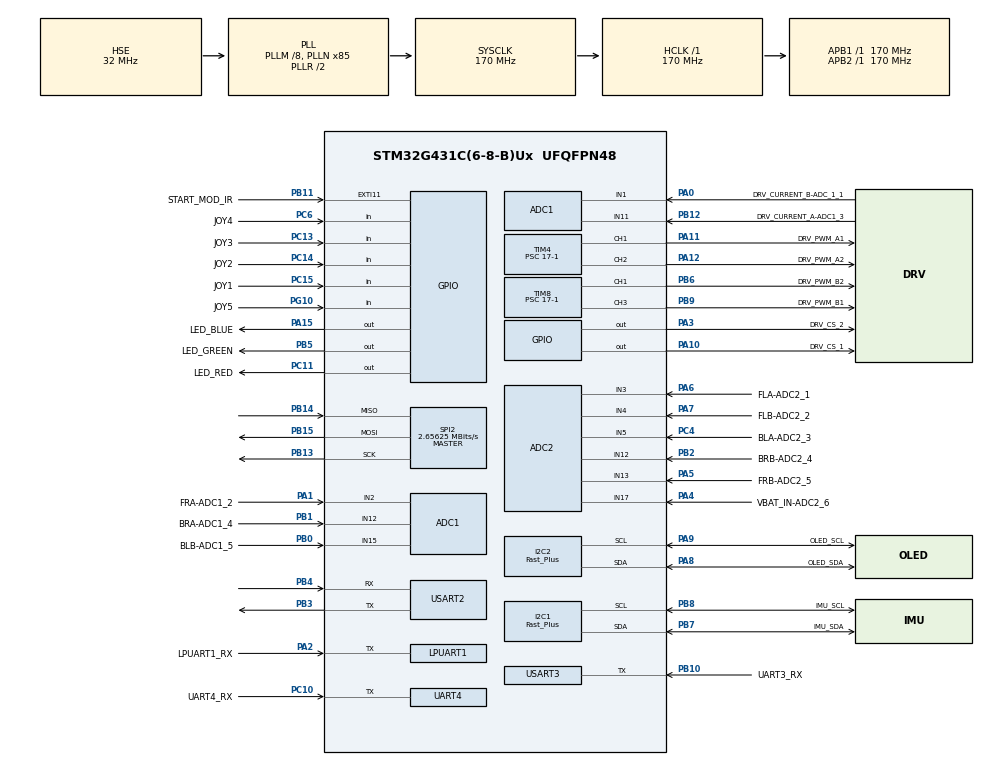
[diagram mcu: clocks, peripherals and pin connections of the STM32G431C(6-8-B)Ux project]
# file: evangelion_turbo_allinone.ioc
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ADC1.Channel-0\#ChannelRegularConversion=ADC_CHANNEL_1
ADC1.Channel-1\#ChannelRegularConversion=ADC_CHANNEL_2
ADC1.Channel-2\#ChannelRegularConversion=ADC_CHANNEL_11
ADC1.Channel-3\#ChannelRegularConversion=ADC_CHANNEL_12
ADC1.Channel-4\#ChannelRegularConversion=ADC_CHANNEL_15
ADC1.Channel-8\#ChannelRegularConversion=ADC_CHANNEL_TEMPSENSOR_ADC1
ADC1.ContinuousConvMode=ENABLE
ADC1.DMAContinuousRequests=ENABLE
ADC1.NbrOfConversion=6
ADC1.NbrOfConversionFlag=1
ADC1.OffsetNumber-0\#ChannelRegularConversion=ADC_OFFSET_NONE
ADC1.OffsetNumber-1\#ChannelRegularConversion=ADC_OFFSET_NONE
ADC1.OffsetNumber-2\#ChannelRegularConversion=ADC_OFFSET_NONE
ADC1.OffsetNumber-3\#ChannelRegularConversion=ADC_OFFSET_NONE
ADC1.OffsetNumber-4\#ChannelRegularConversion=ADC_OFFSET_NONE
ADC1.OffsetNumber-8\#ChannelRegularConversion=ADC_OFFSET_NONE
ADC1.Overrun=ADC_OVR_DATA_OVERWRITTEN
ADC1.Rank-0\#ChannelRegularConversion=1
ADC1.Rank-1\#ChannelRegularConversion=2
ADC1.Rank-2\#ChannelRegularConversion=3
ADC1.Rank-3\#ChannelRegularConversion=4
ADC1.Rank-4\#ChannelRegularConversion=5
ADC1.Rank-8\#ChannelRegularConversion=6
ADC1.SamplingTime-0\#ChannelRegularConversion=ADC_SAMPLETIME_640CYCLES_5
ADC1.SamplingTime-1\#ChannelRegularConversion=ADC_SAMPLETIME_92CYCLES_5
ADC1.SamplingTime-2\#ChannelRegularConversion=ADC_SAMPLETIME_92CYCLES_5
ADC1.SamplingTime-3\#ChannelRegularConversion=ADC_SAMPLETIME_92CYCLES_5
ADC1.SamplingTime-4\#ChannelRegularConversion=ADC_SAMPLETIME_92CYCLES_5
ADC1.SamplingTime-8\#ChannelRegularConversion=ADC_SAMPLETIME_640CYCLES_5
ADC1.master=1
ADC2.Channel-0\#ChannelRegularConversion=ADC_CHANNEL_3
ADC2.Channel-1\#ChannelRegularConversion=ADC_CHANNEL_4
ADC2.Channel-2\#ChannelRegularConversion=ADC_CHANNEL_5
ADC2.Channel-3\#ChannelRegularConversion=ADC_CHANNEL_12
ADC2.Channel-4\#ChannelRegularConversion=ADC_CHANNEL_13
ADC2.Channel-5\#ChannelRegularConversion=ADC_CHANNEL_17
ADC2.ContinuousConvMode=ENABLE
ADC2.DMAContinuousRequests=ENABLE
ADC2.NbrOfConversion=6
ADC2.NbrOfConversionFlag=1
ADC2.OffsetNumber-0\#ChannelRegularConversion=ADC_OFFSET_NONE
ADC2.OffsetNumber-1\#ChannelRegularConversion=ADC_OFFSET_NONE
ADC2.OffsetNumber-2\#ChannelRegularConversion=ADC_OFFSET_NONE
ADC2.OffsetNumber-3\#ChannelRegularConversion=ADC_OFFSET_NONE
ADC2.OffsetNumber-4\#ChannelRegularConversion=ADC_OFFSET_NONE
ADC2.OffsetNumber-5\#ChannelRegularConversion=ADC_OFFSET_NONE
ADC2.Overrun=ADC_OVR_DATA_OVERWRITTEN
ADC2.Rank-0\#ChannelRegularConversion=1
ADC2.Rank-1\#ChannelRegularConversion=2
ADC2.Rank-2\#ChannelRegularConversion=3
ADC2.Rank-3\#ChannelRegularConversion=4
ADC2.Rank-4\#ChannelRegularConversion=5
ADC2.Rank-5\#ChannelRegularConversion=6
ADC2.SamplingTime-0\#ChannelRegularConversion=ADC_SAMPLETIME_92CYCLES_5
ADC2.SamplingTime-1\#ChannelRegularConversion=ADC_SAMPLETIME_92CYCLES_5
ADC2.SamplingTime-2\#ChannelRegularConversion=ADC_SAMPLETIME_92CYCLES_5
ADC2.SamplingTime-3\#ChannelRegularConversion=ADC_SAMPLETIME_92CYCLES_5
ADC2.SamplingTime-4\#ChannelRegularConversion=ADC_SAMPLETIME_92CYCLES_5
ADC2.SamplingTime-5\#ChannelRegularConversion=ADC_SAMPLETIME_92CYCLES_5
Dma.ADC1.7.Direction=DMA_PERIPH_TO_MEMORY
Dma.ADC1.7.EventEnable=DISABLE
Dma.ADC1.7.Instance=DMA2_Channel2
Dma.ADC1.7.MemDataAlignment=DMA_MDATAALIGN_HALFWORD
Dma.ADC1.7.MemInc=DMA_MINC_ENABLE
Dma.ADC1.7.Mode=DMA_CIRCULAR
Dma.ADC1.7.PeriphDataAlignment=DMA_PDATAALIGN_HALFWORD
Dma.ADC1.7.PeriphInc=DMA_PINC_DISABLE
Dma.ADC1.7.Polarity=HAL_DMAMUX_REQ_GEN_RISING
Dma.ADC1.7.Priority=DMA_PRIORITY_MEDIUM
Dma.ADC1.7.RequestNumber=1
Dma.ADC1.7.SignalID=NONE
Dma.ADC1.7.SyncEnable=DISABLE
Dma.ADC1.7.SyncPolarity=HAL_DMAMUX_SYNC_NO_EVENT
Dma.ADC1.7.SyncRequestNumber=1
Dma.ADC1.7.SyncSignalID=NONE
Dma.ADC2.6.Direction=DMA_PERIPH_TO_MEMORY
Dma.ADC2.6.EventEnable=DISABLE
Dma.ADC2.6.Instance=DMA2_Channel1
Dma.ADC2.6.MemDataAlignment=DMA_MDATAALIGN_HALFWORD
Dma.ADC2.6.MemInc=DMA_MINC_ENABLE
Dma.ADC2.6.Mode=DMA_CIRCULAR
Dma.ADC2.6.PeriphDataAlignment=DMA_PDATAALIGN_HALFWORD
Dma.ADC2.6.PeriphInc=DMA_PINC_DISABLE
Dma.ADC2.6.Polarity=HAL_DMAMUX_REQ_GEN_RISING
Dma.ADC2.6.Priority=DMA_PRIORITY_MEDIUM
Dma.ADC2.6.RequestNumber=1
Dma.ADC2.6.SignalID=NONE
Dma.ADC2.6.SyncEnable=DISABLE
Dma.ADC2.6.SyncPolarity=HAL_DMAMUX_SYNC_NO_EVENT
Dma.ADC2.6.SyncRequestNumber=1
Dma.ADC2.6.SyncSignalID=NONE
Dma.I2C1_RX.0.Direction=DMA_PERIPH_TO_MEMORY
Dma.I2C1_RX.0.EventEnable=DISABLE
Dma.I2C1_RX.0.Instance=DMA1_Channel1
Dma.I2C1_RX.0.MemDataAlignment=DMA_MDATAALIGN_BYTE
Dma.I2C1_RX.0.MemInc=DMA_MINC_ENABLE
Dma.I2C1_RX.0.Mode=DMA_NORMAL
Dma.I2C1_RX.0.PeriphDataAlignment=DMA_PDATAALIGN_BYTE
Dma.I2C1_RX.0.PeriphInc=DMA_PINC_DISABLE
Dma.I2C1_RX.0.Polarity=HAL_DMAMUX_REQ_GEN_RISING
Dma.I2C1_RX.0.Priority=DMA_PRIORITY_LOW
Dma.I2C1_RX.0.RequestNumber=1
Dma.I2C1_RX.0.SignalID=NONE
Dma.I2C1_RX.0.SyncEnable=DISABLE
Dma.I2C1_RX.0.SyncPolarity=HAL_DMAMUX_SYNC_NO_EVENT
Dma.I2C1_RX.0.SyncRequestNumber=1
Dma.I2C1_RX.0.SyncSignalID=NONE
Dma.I2C2_TX.1.Direction=DMA_MEMORY_TO_PERIPH
Dma.I2C2_TX.1.EventEnable=DISABLE
Dma.I2C2_TX.1.Instance=DMA1_Channel2
Dma.I2C2_TX.1.MemDataAlignment=DMA_MDATAALIGN_BYTE
Dma.I2C2_TX.1.MemInc=DMA_MINC_ENABLE
Dma.I2C2_TX.1.Mode=DMA_NORMAL
Dma.I2C2_TX.1.PeriphDataAlignment=DMA_PDATAALIGN_BYTE
Dma.I2C2_TX.1.PeriphInc=DMA_PINC_DISABLE
Dma.I2C2_TX.1.Polarity=HAL_DMAMUX_REQ_GEN_RISING
Dma.I2C2_TX.1.Priority=DMA_PRIORITY_LOW
Dma.I2C2_TX.1.RequestNumber=1
Dma.I2C2_TX.1.SignalID=NONE
Dma.I2C2_TX.1.SyncEnable=DISABLE
Dma.I2C2_TX.1.SyncPolarity=HAL_DMAMUX_SYNC_NO_EVENT
Dma.I2C2_TX.1.SyncRequestNumber=1
Dma.I2C2_TX.1.SyncSignalID=NONE
Dma.LPUART1_RX.5.Direction=DMA_PERIPH_TO_MEMORY
Dma.LPUART1_RX.5.EventEnable=DISABLE
Dma.LPUART1_RX.5.Instance=DMA1_Channel6
Dma.LPUART1_RX.5.MemDataAlignment=DMA_MDATAALIGN_BYTE
Dma.LPUART1_RX.5.MemInc=DMA_MINC_ENABLE
Dma.LPUART1_RX.5.Mode=DMA_CIRCULAR
Dma.LPUART1_RX.5.PeriphDataAlignment=DMA_PDATAALIGN_BYTE
Dma.LPUART1_RX.5.PeriphInc=DMA_PINC_DISABLE
Dma.LPUART1_RX.5.Polarity=HAL_DMAMUX_REQ_GEN_RISING
Dma.LPUART1_RX.5.Priority=DMA_PRIORITY_HIGH
Dma.LPUART1_RX.5.RequestNumber=1
Dma.LPUART1_RX.5.SignalID=NONE
Dma.LPUART1_RX.5.SyncEnable=DISABLE
Dma.LPUART1_RX.5.SyncPolarity=HAL_DMAMUX_SYNC_NO_EVENT
Dma.LPUART1_RX.5.SyncRequestNumber=1
Dma.LPUART1_RX.5.SyncSignalID=NONE
Dma.Request0=I2C1_RX
Dma.Request1=I2C2_TX
Dma.Request2=USART2_RX
Dma.Request3=UART4_RX
Dma.Request4=USART3_RX
Dma.Request5=LPUART1_RX
Dma.Request6=ADC2
Dma.Request7=ADC1
Dma.UART4_RX.3.Direction=DMA_PERIPH_TO_MEMORY
Dma.UART4_RX.3.EventEnable=DISABLE
Dma.UART4_RX.3.Instance=DMA1_Channel4
Dma.UART4_RX.3.MemDataAlignment=DMA_MDATAALIGN_BYTE
Dma.UART4_RX.3.MemInc=DMA_MINC_ENABLE
Dma.UART4_RX.3.Mode=DMA_CIRCULAR
Dma.UART4_RX.3.PeriphDataAlignment=DMA_PDATAALIGN_BYTE
Dma.UART4_RX.3.PeriphInc=DMA_PINC_DISABLE
Dma.UART4_RX.3.Polarity=HAL_DMAMUX_REQ_GEN_RISING
Dma.UART4_RX.3.Priority=DMA_PRIORITY_HIGH
Dma.UART4_RX.3.RequestNumber=1
Dma.UART4_RX.3.SignalID=NONE
Dma.UART4_RX.3.SyncEnable=DISABLE
Dma.UART4_RX.3.SyncPolarity=HAL_DMAMUX_SYNC_NO_EVENT
Dma.UART4_RX.3.SyncRequestNumber=1
Dma.UART4_RX.3.SyncSignalID=NONE
Dma.USART2_RX.2.Direction=DMA_PERIPH_TO_MEMORY
Dma.USART2_RX.2.EventEnable=DISABLE
Dma.USART2_RX.2.Instance=DMA1_Channel3
Dma.USART2_RX.2.MemDataAlignment=DMA_MDATAALIGN_BYTE
Dma.USART2_RX.2.MemInc=DMA_MINC_ENABLE
Dma.USART2_RX.2.Mode=DMA_CIRCULAR
Dma.USART2_RX.2.PeriphDataAlignment=DMA_PDATAALIGN_BYTE
Dma.USART2_RX.2.PeriphInc=DMA_PINC_DISABLE
Dma.USART2_RX.2.Polarity=HAL_DMAMUX_REQ_GEN_RISING
Dma.USART2_RX.2.Priority=DMA_PRIORITY_HIGH
Dma.USART2_RX.2.RequestNumber=1
Dma.USART2_RX.2.SignalID=NONE
Dma.USART2_RX.2.SyncEnable=DISABLE
Dma.USART2_RX.2.SyncPolarity=HAL_DMAMUX_SYNC_NO_EVENT
Dma.USART2_RX.2.SyncRequestNumber=1
Dma.USART2_RX.2.SyncSignalID=NONE
Dma.USART3_RX.4.Direction=DMA_PERIPH_TO_MEMORY
Dma.USART3_RX.4.EventEnable=DISABLE
Dma.USART3_RX.4.Instance=DMA1_Channel5
Dma.USART3_RX.4.MemDataAlignment=DMA_MDATAALIGN_BYTE
Dma.USART3_RX.4.MemInc=DMA_MINC_ENABLE
Dma.USART3_RX.4.Mode=DMA_CIRCULAR
Dma.USART3_RX.4.PeriphDataAlignment=DMA_PDATAALIGN_BYTE
Dma.USART3_RX.4.PeriphInc=DMA_PINC_DISABLE
Dma.USART3_RX.4.Polarity=HAL_DMAMUX_REQ_GEN_RISING
Dma.USART3_RX.4.Priority=DMA_PRIORITY_HIGH
Dma.USART3_RX.4.RequestNumber=1
Dma.USART3_RX.4.SignalID=NONE
Dma.USART3_RX.4.SyncEnable=DISABLE
Dma.USART3_RX.4.SyncPolarity=HAL_DMAMUX_SYNC_NO_EVENT
Dma.USART3_RX.4.SyncRequestNumber=1
Dma.USART3_RX.4.SyncSignalID=NONE
I2C1.I2C_Speed_Mode=I2C_Fast_Plus
I2C1.Timing=0x4052060F
I2C2.I2C_Speed_Mode=I2C_Fast_Plus
I2C2.Timing=0x4052060F
LPUART1.BaudRate=115200
LPUART1.Mode=UART_MODE_RX
Mcu.Family=STM32G4
Mcu.Name=STM32G431C(6-8-B)Ux
Mcu.Package=UFQFPN48
NVIC.DMA1_Channel1_IRQn=true\:0\:0\:false\:false\:true\:false\:true\:true
NVIC.DMA1_Channel2_IRQn=true\:0\:0\:false\:false\:true\:false\:true\:true
NVIC.DMA1_Channel3_IRQn=true\:0\:0\:false\:false\:true\:false\:true\:true
NVIC.DMA1_Channel4_IRQn=true\:0\:0\:false\:false\:true\:false\:true\:true
NVIC.DMA1_Channel5_IRQn=true\:0\:0\:false\:false\:true\:false\:true\:true
NVIC.DMA1_Channel6_IRQn=true\:0\:0\:false\:false\:true\:false\:true\:true
NVIC.DMA2_Channel1_IRQn=true\:1\:0\:true\:false\:true\:false\:true\:true
NVIC.DMA2_Channel2_IRQn=true\:1\:0\:true\:false\:true\:false\:true\:true
NVIC.EXTI15_10_IRQn=true\:0\:0\:false\:false\:true\:true\:true\:true
NVIC.I2C1_EV_IRQn=true\:8\:0\:true\:false\:true\:true\:true\:true
NVIC.I2C2_EV_IRQn=true\:15\:0\:true\:false\:true\:true\:true\:true
NVIC.LPUART1_IRQn=true\:7\:0\:true\:false\:true\:true\:true\:true
NVIC.PriorityGroup=NVIC_PRIORITYGROUP_4
NVIC.SPI2_IRQn=true\:2\:0\:true\:false\:true\:true\:true\:true
NVIC.TIM1_BRK_TIM15_IRQn=true\:1\:0\:true\:false\:true\:true\:true\:true
NVIC.TIM1_TRG_COM_TIM17_IRQn=true\:1\:0\:true\:false\:true\:true\:true\:true
NVIC.TIM1_UP_TIM16_IRQn=true\:1\:0\:true\:false\:true\:true\:true\:true
NVIC.TIM2_IRQn=true\:1\:0\:true\:false\:true\:true\:true\:true
NVIC.TIM6_DAC_IRQn=true\:1\:0\:true\:false\:true\:true\:true\:true
NVIC.TIM7_IRQn=true\:1\:0\:true\:false\:true\:true\:true\:true
NVIC.UART4_IRQn=true\:7\:0\:true\:false\:true\:true\:true\:true
NVIC.USART2_IRQn=true\:7\:0\:true\:false\:true\:true\:true\:true
NVIC.USART3_IRQn=true\:7\:0\:true\:false\:true\:true\:true\:true
PA0.GPIO_Label=DRV_CURRENT_B-ADC_1_1
PA0.Mode=IN1-Single-Ended
PA0.Signal=ADC1_IN1
PA1.GPIO_Label=FRA-ADC1_2
PA1.Mode=IN2-Single-Ended
PA1.Signal=ADC1_IN2
PA10.GPIO_Label=DRV_CS_1
PA10.PinState=GPIO_PIN_SET
PA10.Signal=GPIO_Output
PA11.GPIO_Label=DRV_PWM_A1
PA11.Signal=S_TIM4_CH1
PA12.GPIO_Label=DRV_PWM_A2
PA12.Signal=S_TIM4_CH2
PA13.Mode=Serial_Wire
PA13.Signal=SYS_JTMS-SWDIO
PA14.Mode=Serial_Wire
PA14.Signal=SYS_JTCK-SWCLK
PA15.GPIO_Label=LED_BLUE
PA15.Signal=GPIO_Output
PA2.GPIO_Label=LPUART1_RX
PA2.Mode=Half_duplex(single_wire_mode)
PA2.Signal=LPUART1_TX
PA3.GPIO_Label=DRV_CS_2
PA3.PinState=GPIO_PIN_SET
PA3.Signal=GPIO_Output
PA4.GPIO_Label=VBAT_IN-ADC2_6
PA4.Mode=IN17-Single-Ended
PA4.Signal=ADC2_IN17
PA5.GPIO_Label=FRB-ADC2_5
PA5.Mode=IN13-Single-Ended
PA5.Signal=ADC2_IN13
PA6.GPIO_Label=FLA-ADC2_1
PA6.Mode=IN3-Single-Ended
PA6.Signal=ADC2_IN3
PA7.GPIO_Label=FLB-ADC2_2
PA7.Mode=IN4-Single-Ended
PA7.Signal=ADC2_IN4
PA8.GPIO_Label=OLED_SDA
PA8.Mode=I2C
PA8.Signal=I2C2_SDA
PA9.GPIO_Label=OLED_SCL
PA9.Mode=I2C
PA9.Signal=I2C2_SCL
PB0.GPIO_Label=BLB-ADC1_5
PB0.Mode=IN15-Single-Ended
PB0.Signal=ADC1_IN15
PB1.GPIO_Label=BRA-ADC1_4
PB1.Mode=IN12-Single-Ended
PB1.Signal=ADC1_IN12
PB10.GPIO_Label=UART3_RX
PB10.Mode=Half_duplex(single_wire_mode)
PB10.Signal=USART3_TX
PB11.GPIO_Label=START_MOD_IR
PB11.GPIO_ModeDefaultEXTI=GPIO_MODE_IT_RISING_FALLING
PB11.Signal=GPXTI11
PB12.GPIO_Label=DRV_CURRENT_A-ADC1_3
PB12.Mode=IN11-Single-Ended
PB12.Signal=ADC1_IN11
PB13.GPIO_Mode=GPIO_MODE_AF_PP
PB13.GPIO_PuPd=GPIO_NOPULL
PB13.GPIO_Speed=GPIO_SPEED_FREQ_LOW
PB13.Mode=Full_Duplex_Master
PB13.Signal=SPI2_SCK
PB14.GPIO_Mode=GPIO_MODE_AF_PP
PB14.GPIO_PuPd=GPIO_NOPULL
PB14.GPIO_Speed=GPIO_SPEED_FREQ_LOW
PB14.Mode=Full_Duplex_Master
PB14.Signal=SPI2_MISO
PB15.GPIO_Mode=GPIO_MODE_AF_PP
PB15.GPIO_PuPd=GPIO_NOPULL
PB15.GPIO_Speed=GPIO_SPEED_FREQ_LOW
PB15.Mode=Full_Duplex_Master
PB15.Signal=SPI2_MOSI
PB2.GPIO_Label=BRB-ADC2_4
PB2.Mode=IN12-Single-Ended
PB2.Signal=ADC2_IN12
PB3.Mode=Asynchronous
PB3.Signal=USART2_TX
PB4.Mode=Asynchronous
PB4.Signal=USART2_RX
PB5.GPIO_Label=LED_GREEN
PB5.Signal=GPIO_Output
PB6.GPIO_Label=DRV_PWM_B2
PB6.Signal=S_TIM8_CH1
PB7.GPIO_Label=IMU_SDA
PB7.Mode=I2C
PB7.Signal=I2C1_SDA
PB8-BOOT0.GPIO_Label=IMU_SCL
PB8-BOOT0.Mode=I2C
PB8-BOOT0.Signal=I2C1_SCL
PB9.GPIO_Label=DRV_PWM_B1
PB9.Signal=S_TIM8_CH3
PC10.GPIO_Label=UART4_RX
PC10.Mode=Half_duplex(single_wire_mode)
PC10.Signal=UART4_TX
PC11.GPIO_Label=LED_RED
PC11.Signal=GPIO_Output
PC13.GPIO_Label=JOY3
PC13.GPIO_PuPd=GPIO_PULLUP
PC13.Signal=GPIO_Input
PC14-OSC32_IN.GPIO_Label=JOY2
PC14-OSC32_IN.GPIO_PuPd=GPIO_PULLUP
PC14-OSC32_IN.Signal=GPIO_Input
PC15-OSC32_OUT.GPIO_Label=JOY1
PC15-OSC32_OUT.GPIO_PuPd=GPIO_PULLUP
PC15-OSC32_OUT.Signal=GPIO_Input
PC4.GPIO_Label=BLA-ADC2_3
PC4.Mode=IN5-Single-Ended
PC4.Signal=ADC2_IN5
PC6.GPIO_Label=JOY4
PC6.GPIO_PuPd=GPIO_PULLUP
PC6.Signal=GPIO_Input
PF0-OSC_IN.Mode=HSE-External-Oscillator
PF0-OSC_IN.Signal=RCC_OSC_IN
PF1-OSC_OUT.Mode=HSE-External-Oscillator
PF1-OSC_OUT.Signal=RCC_OSC_OUT
PG10-NRST.GPIO_Label=JOY5
PG10-NRST.GPIO_PuPd=GPIO_PULLUP
PG10-NRST.Signal=GPIO_Input
ProjectManager.HeapSize=0x200
ProjectManager.StackSize=0x400
ProjectManager.TargetToolchain=STM32CubeIDE
RCC.ADC12Freq_Value=170000000
RCC.AHBFreq_Value=170000000
RCC.APB1Freq_Value=170000000
RCC.APB1TimFreq_Value=170000000
RCC.APB2Freq_Value=170000000
RCC.APB2TimFreq_Value=170000000
RCC.CortexFreq_Value=170000000
RCC.EXTERNAL_CLOCK_VALUE=12288000
RCC.EnbaleCSS=true
RCC.HCLKFreq_Value=170000000
RCC.HSE_Timout=100
RCC.HSE_VALUE=32000000
RCC.HSI48_VALUE=48000000
RCC.HSI_VALUE=16000000
RCC.LSE_VALUE=32768
RCC.PLLM=RCC_PLLM_DIV8
RCC.PLLN=85
RCC.PLLSourceVirtual=RCC_PLLSOURCE_HSE
RCC.SYSCLKFreq_VALUE=170000000
RCC.SYSCLKSource=RCC_SYSCLKSOURCE_PLLCLK
RCC.USBFreq_Value=170000000
RCC.VCOOutputFreq_Value=340000000
SH.S_TIM4_CH1.0=TIM4_CH1,PWM Generation1 CH1
SH.S_TIM4_CH2.0=TIM4_CH2,PWM Generation2 CH2
SH.S_TIM8_CH1.0=TIM8_CH1,PWM Generation1 CH1
SH.S_TIM8_CH3.0=TIM8_CH3,PWM Generation3 CH3
SPI2.BaudRatePrescaler=SPI_BAUDRATEPRESCALER_64
SPI2.CLKPhase=SPI_PHASE_2EDGE
SPI2.CalculateBaudRate=2.65625 MBits/s
SPI2.DataSize=SPI_DATASIZE_16BIT
SPI2.Direction=SPI_DIRECTION_2LINES
SPI2.Mode=SPI_MODE_MASTER
SPI2.VirtualType=VM_MASTER
TIM1.Prescaler=17000-1
TIM15.PeriodNoDither=1000-1
TIM15.Prescaler=170-1
TIM16.PeriodNoDither=1000-1
TIM16.Prescaler=1700-1
TIM17.PeriodNoDither=4000-1
TIM17.Prescaler=1700-1
TIM2.PeriodNoDither=65535
TIM2.Prescaler=17000-1
TIM4.Channel-PWM\ Generation1\ CH1=TIM_CHANNEL_1
TIM4.Channel-PWM\ Generation2\ CH2=TIM_CHANNEL_2
TIM4.PeriodNoDither=1000-1
TIM4.Prescaler=17-1
TIM6.PeriodNoDither=5000-1
TIM6.Prescaler=1700-1
TIM7.PeriodNoDither=65534
TIM7.Prescaler=170-1
TIM8.Channel-PWM\ Generation1\ CH1=TIM_CHANNEL_1
TIM8.Channel-PWM\ Generation3\ CH3=TIM_CHANNEL_3
TIM8.PeriodNoDither=1000-1
TIM8.Prescaler=17-1
UART4.Mode=MODE_RX
USART2.VirtualMode-Asynchronous=VM_ASYNC
USART3.Mode=MODE_RX
USART3.VirtualMode-Half_duplex(single_wire_mode)=VM_ASYNC
VP_ADC1_TempSens_Input.Mode=IN-TempSens
VP_SYS_VS_DBSignals.Mode=DisableDeadBatterySignals
VP_TIM15_VS_ClockSourceINT.Mode=Internal
VP_TIM16_VS_ClockSourceINT.Mode=Enable_Timer
VP_TIM17_VS_ClockSourceINT.Mode=Enable_Timer
VP_TIM1_VS_OPM.Mode=OPM_bit
VP_TIM2_VS_OPM.Mode=OPM_bit
VP_TIM6_VS_ClockSourceINT.Mode=Enable_Timer
VP_TIM7_VS_ClockSourceINT.Mode=Enable_Timer
board=custom

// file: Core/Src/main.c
/* USER CODE BEGIN Header */
/**
  ******************************************************************************
  * @file           : main.c
  * @brief          : Main program body
  ******************************************************************************
  * @attention
  *
  * Copyright (c) 2026 STMicroelectronics.
  * All rights reserved.
  *
  * This software is licensed under terms that can be found in the LICENSE file
  * in the root directory of this software component.
  * If no LICENSE file comes with this software, it is provided AS-IS.
  *
  ******************************************************************************
  */
/* USER CODE END Header */
#include "main.h"

/* USER CODE BEGIN Includes */
#include "MY_INCLUDES.h"
#include "start_module.h"
#include "TFLUNA.h"
#include "ADC_READOUT.h"
#include "fonts.h"
#include "ssd1306.h"
#include "DRIVERS.h"
#include "WATCHDOG_AND_INTERFACE.h"
#include "ATCK_MODES.h"
/* USER CODE END Includes */

/* USER CODE BEGIN PTD */
/* raw[] / hal_status[] / hal_error[] are indexed by register address 0..5.
 * Data fields are meaningful only for successful transfers with valid headers.
 */

/*
	IMU: LSM6DSOX
	DRV: DRV8873SPWR
	MCU: STM32G431CBU6
	TIM6: about 20Hz, start mod led
	TIM7: 1MHz clock, 65.5ms , start mod
	TIM15: 1kHz IT
	TIM16: 100Hz IT
	TIM17: 25Hz IT
*/

/* USER CODE END PTD */

ADC_HandleTypeDef hadc1;
ADC_HandleTypeDef hadc2;
DMA_HandleTypeDef hdma_adc1;
DMA_HandleTypeDef hdma_adc2;

I2C_HandleTypeDef hi2c1;
I2C_HandleTypeDef hi2c2;
DMA_HandleTypeDef hdma_i2c1_rx;
DMA_HandleTypeDef hdma_i2c2_tx;

UART_HandleTypeDef hlpuart1;
UART_HandleTypeDef huart4;
UART_HandleTypeDef huart2;
UART_HandleTypeDef huart3;
DMA_HandleTypeDef hdma_lpuart1_rx;
DMA_HandleTypeDef hdma_uart4_rx;
DMA_HandleTypeDef hdma_usart2_rx;
DMA_HandleTypeDef hdma_usart3_rx;

SPI_HandleTypeDef hspi2;

TIM_HandleTypeDef htim1;
TIM_HandleTypeDef htim2;
TIM_HandleTypeDef htim4;
TIM_HandleTypeDef htim6;
TIM_HandleTypeDef htim7;
TIM_HandleTypeDef htim8;
TIM_HandleTypeDef htim15;
TIM_HandleTypeDef htim16;
TIM_HandleTypeDef htim17;

/* USER CODE BEGIN PV */
uint32_t dupa=0;

//performance!
static uint32_t last_total = 0;
static uint32_t last_idle = 0;
volatile uint32_t cpu_idle_cycles = 0;
volatile uint32_t cpu_load_permille = 0;
volatile uint8_t MCU_LOAD = 0;

LidarSensors_t Lunas;
LinesSensors_t Lines;
JoystickMode_t JoystickState;
Evangelion_t Eva;
MotorsSettingsInfo_t Motors;
IMUInfo_t IMU;

uint8_t lastSeen = LEFT;
uint8_t before_attack_rotation_direction;

volatile uint16_t ADC1_BUFFER[6];
volatile uint16_t ADC2_BUFFER[6];
const float BATTERY_CONSTANT = BATTERY_CONST;
/* USER CODE END PV */

void SystemClock_Config(void);
static void MX_GPIO_Init(void);
static void MX_DMA_Init(void);
static void MX_ADC1_Init(void);
static void MX_ADC2_Init(void);
static void MX_I2C1_Init(void);
static void MX_I2C2_Init(void);
static void MX_LPUART1_UART_Init(void);
static void MX_UART4_Init(void);
static void MX_USART2_UART_Init(void);
static void MX_USART3_UART_Init(void);
static void MX_SPI2_Init(void);
static void MX_TIM4_Init(void);
static void MX_TIM8_Init(void);
static void MX_TIM15_Init(void);
static void MX_TIM16_Init(void);
static void MX_TIM17_Init(void);
static void MX_TIM7_Init(void);
static void MX_TIM6_Init(void);
static void MX_TIM1_Init(void);
static void MX_TIM2_Init(void);
/* USER CODE BEGIN PFP */
static inline void DWT_Init(void);
void LOAD_PERFORMANCE_CALCULATION(void);
/* USER CODE END PFP */

/* USER CODE BEGIN 0 */
/* DRV8873 datasheet, sections 7.5 and 7.6:
 * read = bit 14, address = bits 13:9; response = status:8 | register:8.
 * Reads neither clear latched faults nor change the bridge configuration.
 */

/* USER CODE END 0 */

int main(void)
{

  /* USER CODE BEGIN 1 */
	Lunas.FrontLeft.huartRX = &hlpuart1;
	Lunas.FrontRight.huartRX = &huart2;
	Lunas.BackLeft.huartRX = &huart3;
	Lunas.BackRight.huartRX = &huart4;
	Lunas.huartTX = &huart2;
	Lunas.FrontLeft.RXsize = sizeof Lunas.FrontLeft.RX;
	Lunas.FrontRight.RXsize = sizeof Lunas.FrontRight.RX;
	Lunas.BackLeft.RXsize = sizeof Lunas.BackLeft.RX;
	Lunas.BackRight.RXsize = sizeof Lunas.BackRight.RX;

	JoystickState = _NOTHING;

  /* USER CODE END 1 */

  /* MCU Configuration--------------------------------------------------------*/

  /* Reset of all peripherals, Initializes the Flash interface and the Systick. */
  HAL_Init();

  /* USER CODE BEGIN Init */
  HAL_Delay(INIT_DELAY*2);

  //blink leds
  HAL_GPIO_WritePin(LED_RED_GPIO_Port, LED_RED_Pin, 1);
  HAL_GPIO_WritePin(LED_GREEN_GPIO_Port, LED_GREEN_Pin, 1);
  HAL_GPIO_WritePin(LED_BLUE_GPIO_Port, LED_BLUE_Pin, 1);

  //Disable SPI for drivers
  HAL_GPIO_WritePin(DRV_CS_1_GPIO_Port, DRV_CS_1_Pin, 1);
  HAL_GPIO_WritePin(DRV_CS_2_GPIO_Port, DRV_CS_2_Pin, 1);

  /* USER CODE END Init */

  /* Configure the system clock */
  SystemClock_Config();

  /* Initialize all configured peripherals */
  MX_GPIO_Init();
  MX_DMA_Init();
  MX_ADC1_Init();
  MX_ADC2_Init();
  MX_I2C1_Init();
  MX_I2C2_Init();
  MX_LPUART1_UART_Init();
  MX_UART4_Init();
  MX_USART2_UART_Init();
  MX_USART3_UART_Init();
  MX_SPI2_Init();
  MX_TIM4_Init();
  MX_TIM8_Init();
  MX_TIM15_Init();
  MX_TIM16_Init();
  MX_TIM17_Init();
  MX_TIM7_Init();
  MX_TIM6_Init();
  MX_TIM1_Init();
  MX_TIM2_Init();
  /* USER CODE BEGIN 2 */

	//============================= OLED
	if(ssd1306_Init()==0)
		Error_Handler();
	ssd1306_Clear();
	ssd1306_SetColor(White);
	ssd1306_Fill();
	ssd1306_UpdateScreen();
	HAL_Delay(INIT_DELAY);

	ssd1306_Clear();
	_ssd1306_WriteInTheMiddle("TURBO", 20, BIG);
	_ssd1306_WriteInTheMiddle("EVANGELION", 40, BIG);
	ssd1306_UpdateScreen();
	HAL_Delay(INIT_DELAY);

	//============================= START MOD
	ssd1306_Clear();
	_ssd1306_WriteInTheMiddle("INIT", 10, BIG);
	_ssd1306_WriteInTheMiddle("START MODULE...", 30, SMALL);
	ssd1306_UpdateScreen();
	HAL_Delay(INIT_DELAY);
	StartModule_Startup();

	//============================= LIDARS
	ssd1306_Clear();
	_ssd1306_WriteInTheMiddle("INIT", 10, BIG);
	_ssd1306_WriteInTheMiddle("LIDARs INIT...", 30, SMALL);
	ssd1306_UpdateScreen();
	HAL_Delay(INIT_DELAY);
	if(TFLUNAs_INIT(&Lunas) != HAL_OK) Error_Handler();

	//============================= ADCs
	ssd1306_Clear();
	_ssd1306_WriteInTheMiddle("INIT", 10, BIG);
	_ssd1306_WriteInTheMiddle("ADCs...", 30, SMALL);
	ssd1306_UpdateScreen();
	HAL_Delay(INIT_DELAY);
	if(ADC_READOUT_INIT(&hadc1, ADC1_BUFFER, 6) != HAL_OK) Error_Handler();
	if(ADC_READOUT_INIT(&hadc2, ADC2_BUFFER, 6) != HAL_OK) Error_Handler();

	//============================= DRIVERS
	ssd1306_Clear();
	_ssd1306_WriteInTheMiddle("INIT", 10, BIG);
	_ssd1306_WriteInTheMiddle("DRIVERS...", 30, SMALL);
	ssd1306_UpdateScreen();
	HAL_Delay(INIT_DELAY);
	if(DRIVERS_INIT(&hspi2) != HAL_OK) Error_Handler();

	//============================= Performance
	ssd1306_Clear();
	_ssd1306_WriteInTheMiddle("INIT", 10, BIG);
	_ssd1306_WriteInTheMiddle("PERFORMANCE...", 30, SMALL);
	ssd1306_UpdateScreen();
	HAL_Delay(INIT_DELAY);
	DWT_Init();

	//============================= TIMERS
	ssd1306_Clear();
	_ssd1306_WriteInTheMiddle("INIT", 10, BIG);
	_ssd1306_WriteInTheMiddle("TIMERS...", 30, SMALL);
	ssd1306_UpdateScreen();

	HAL_TIM_Base_Start(&htim4); //PWM A
	HAL_TIM_Base_Start(&htim8); //PWM B
	HAL_TIM_PWM_Start(&htim4, TIM_CHANNEL_1);
	HAL_TIM_PWM_Start(&htim4, TIM_CHANNEL_2);
	HAL_TIM_PWM_Start(&htim8, TIM_CHANNEL_1);
	HAL_TIM_PWM_Start(&htim8, TIM_CHANNEL_3);

	HAL_TIM_Base_Start_IT(&htim6); //about 20Hz, start mod led
	HAL_TIM_Base_Start_IT(&htim7); //1MHz clock, 65.5ms, start mod
	HAL_TIM_Base_Start_IT(&htim16); //1kHz
	HAL_TIM_Base_Start_IT(&htim17); //100Hz
	HAL_TIM_Base_Start_IT(&htim15); //25Hz

	//============================= DONE!
	ssd1306_Clear();
	_ssd1306_WriteInTheMiddle("TURBO", 20, BIG);
	_ssd1306_WriteInTheMiddle("EVANGELION", 40, BIG);
	ssd1306_UpdateScreen();
	HAL_GPIO_WritePin(LED_RED_GPIO_Port, LED_RED_Pin, 0);
	HAL_GPIO_WritePin(LED_BLUE_GPIO_Port, LED_BLUE_Pin, 0);
	HAL_GPIO_WritePin(LED_GREEN_GPIO_Port, LED_GREEN_Pin, 0);

  /* USER CODE END 2 */

  /* Infinite loop */
  /* USER CODE BEGIN WHILE */
  while (1)
  {
	uint32_t start = DWT->CYCCNT;
	__WFI();
	cpu_idle_cycles += (DWT->CYCCNT - start);

    /* USER CODE END WHILE */

  }
}

void SystemClock_Config(void)
{
  RCC_OscInitTypeDef RCC_OscInitStruct = {0};
  RCC_ClkInitTypeDef RCC_ClkInitStruct = {0};

  /** Configure the main internal regulator output voltage
  */
  HAL_PWREx_ControlVoltageScaling(PWR_REGULATOR_VOLTAGE_SCALE1_BOOST);

  /** Initializes the RCC Oscillators according to the specified parameters
  * in the RCC_OscInitTypeDef structure.
  */
  RCC_OscInitStruct.OscillatorType = RCC_OSCILLATORTYPE_HSE;
  RCC_OscInitStruct.HSEState = RCC_HSE_ON;
  RCC_OscInitStruct.PLL.PLLState = RCC_PLL_ON;
  RCC_OscInitStruct.PLL.PLLSource = RCC_PLLSOURCE_HSE;
  RCC_OscInitStruct.PLL.PLLM = RCC_PLLM_DIV8;
  RCC_OscInitStruct.PLL.PLLN = 85;
  RCC_OscInitStruct.PLL.PLLP = RCC_PLLP_DIV2;
  RCC_OscInitStruct.PLL.PLLQ = RCC_PLLQ_DIV2;
  RCC_OscInitStruct.PLL.PLLR = RCC_PLLR_DIV2;
  if (HAL_RCC_OscConfig(&RCC_OscInitStruct) != HAL_OK)
  {
    Error_Handler();
  }

  /** Initializes the CPU, AHB and APB buses clocks
  */
  RCC_ClkInitStruct.ClockType = RCC_CLOCKTYPE_HCLK|RCC_CLOCKTYPE_SYSCLK
                              |RCC_CLOCKTYPE_PCLK1|RCC_CLOCKTYPE_PCLK2;
  RCC_ClkInitStruct.SYSCLKSource = RCC_SYSCLKSOURCE_PLLCLK;
  RCC_ClkInitStruct.AHBCLKDivider = RCC_SYSCLK_DIV1;
  RCC_ClkInitStruct.APB1CLKDivider = RCC_HCLK_DIV1;
  RCC_ClkInitStruct.APB2CLKDivider = RCC_HCLK_DIV1;

  if (HAL_RCC_ClockConfig(&RCC_ClkInitStruct, FLASH_LATENCY_4) != HAL_OK)
  {
    Error_Handler();
  }

  /** Enables the Clock Security System
  */
  HAL_RCC_EnableCSS();
}

static void MX_ADC1_Init(void)
{

  ADC_MultiModeTypeDef multimode = {0};
  ADC_ChannelConfTypeDef sConfig = {0};

  /** Common config
  */
  hadc1.Instance = ADC1;
  hadc1.Init.ClockPrescaler = ADC_CLOCK_SYNC_PCLK_DIV4;
  hadc1.Init.Resolution = ADC_RESOLUTION_12B;
  hadc1.Init.DataAlign = ADC_DATAALIGN_RIGHT;
  hadc1.Init.GainCompensation = 0;
  hadc1.Init.ScanConvMode = ADC_SCAN_ENABLE;
  hadc1.Init.EOCSelection = ADC_EOC_SINGLE_CONV;
  hadc1.Init.LowPowerAutoWait = DISABLE;
  hadc1.Init.ContinuousConvMode = ENABLE;
  hadc1.Init.NbrOfConversion = 6;
  hadc1.Init.DiscontinuousConvMode = DISABLE;
  hadc1.Init.ExternalTrigConv = ADC_SOFTWARE_START;
  hadc1.Init.ExternalTrigConvEdge = ADC_EXTERNALTRIGCONVEDGE_NONE;
  hadc1.Init.DMAContinuousRequests = ENABLE;
  hadc1.Init.Overrun = ADC_OVR_DATA_OVERWRITTEN;
  hadc1.Init.OversamplingMode = DISABLE;
  if (HAL_ADC_Init(&hadc1) != HAL_OK)
  {
    Error_Handler();
  }

  /** Configure the ADC multi-mode
  */
  multimode.Mode = ADC_MODE_INDEPENDENT;
  if (HAL_ADCEx_MultiModeConfigChannel(&hadc1, &multimode) != HAL_OK)
  {
    Error_Handler();
  }

  /** Configure Regular Channel
  */
  sConfig.Channel = ADC_CHANNEL_1;
  sConfig.Rank = ADC_REGULAR_RANK_1;
  sConfig.SamplingTime = ADC_SAMPLETIME_640CYCLES_5;
  sConfig.SingleDiff = ADC_SINGLE_ENDED;
  sConfig.OffsetNumber = ADC_OFFSET_NONE;
  sConfig.Offset = 0;
  if (HAL_ADC_ConfigChannel(&hadc1, &sConfig) != HAL_OK)
  {
    Error_Handler();
  }

  /** Configure Regular Channel
  */
  sConfig.Channel = ADC_CHANNEL_2;
  sConfig.Rank = ADC_REGULAR_RANK_2;
  sConfig.SamplingTime = ADC_SAMPLETIME_92CYCLES_5;
  if (HAL_ADC_ConfigChannel(&hadc1, &sConfig) != HAL_OK)
  {
    Error_Handler();
  }

  /** Configure Regular Channel
  */
  sConfig.Channel = ADC_CHANNEL_11;
  sConfig.Rank = ADC_REGULAR_RANK_3;
  if (HAL_ADC_ConfigChannel(&hadc1, &sConfig) != HAL_OK)
  {
    Error_Handler();
  }

  /** Configure Regular Channel
  */
  sConfig.Channel = ADC_CHANNEL_12;
  sConfig.Rank = ADC_REGULAR_RANK_4;
  if (HAL_ADC_ConfigChannel(&hadc1, &sConfig) != HAL_OK)
  {
    Error_Handler();
  }

  /** Configure Regular Channel
  */
  sConfig.Channel = ADC_CHANNEL_15;
  sConfig.Rank = ADC_REGULAR_RANK_5;
  if (HAL_ADC_ConfigChannel(&hadc1, &sConfig) != HAL_OK)
  {
    Error_Handler();
  }

  /** Configure Regular Channel
  */
  sConfig.Channel = ADC_CHANNEL_TEMPSENSOR_ADC1;
  sConfig.Rank = ADC_REGULAR_RANK_6;
  sConfig.SamplingTime = ADC_SAMPLETIME_640CYCLES_5;
  if (HAL_ADC_ConfigChannel(&hadc1, &sConfig) != HAL_OK)
  {
    Error_Handler();
  }

}

static void MX_ADC2_Init(void)
{

  ADC_ChannelConfTypeDef sConfig = {0};

  /** Common config
  */
  hadc2.Instance = ADC2;
  hadc2.Init.ClockPrescaler = ADC_CLOCK_SYNC_PCLK_DIV4;
  hadc2.Init.Resolution = ADC_RESOLUTION_12B;
  hadc2.Init.DataAlign = ADC_DATAALIGN_RIGHT;
  hadc2.Init.GainCompensation = 0;
  hadc2.Init.ScanConvMode = ADC_SCAN_ENABLE;
  hadc2.Init.EOCSelection = ADC_EOC_SINGLE_CONV;
  hadc2.Init.LowPowerAutoWait = DISABLE;
  hadc2.Init.ContinuousConvMode = ENABLE;
  hadc2.Init.NbrOfConversion = 6;
  hadc2.Init.DiscontinuousConvMode = DISABLE;
  hadc2.Init.ExternalTrigConv = ADC_SOFTWARE_START;
  hadc2.Init.ExternalTrigConvEdge = ADC_EXTERNALTRIGCONVEDGE_NONE;
  hadc2.Init.DMAContinuousRequests = ENABLE;
  hadc2.Init.Overrun = ADC_OVR_DATA_OVERWRITTEN;
  hadc2.Init.OversamplingMode = DISABLE;
  if (HAL_ADC_Init(&hadc2) != HAL_OK)
  {
    Error_Handler();
  }

  /** Configure Regular Channel
  */
  sConfig.Channel = ADC_CHANNEL_3;
  sConfig.Rank = ADC_REGULAR_RANK_1;
  sConfig.SamplingTime = ADC_SAMPLETIME_92CYCLES_5;
  sConfig.SingleDiff = ADC_SINGLE_ENDED;
  sConfig.OffsetNumber = ADC_OFFSET_NONE;
  sConfig.Offset = 0;
  if (HAL_ADC_ConfigChannel(&hadc2, &sConfig) != HAL_OK)
  {
    Error_Handler();
  }

  /** Configure Regular Channel
  */
  sConfig.Channel = ADC_CHANNEL_4;
  sConfig.Rank = ADC_REGULAR_RANK_2;
  if (HAL_ADC_ConfigChannel(&hadc2, &sConfig) != HAL_OK)
  {
    Error_Handler();
  }

  /** Configure Regular Channel
  */
  sConfig.Channel = ADC_CHANNEL_5;
  sConfig.Rank = ADC_REGULAR_RANK_3;
  if (HAL_ADC_ConfigChannel(&hadc2, &sConfig) != HAL_OK)
  {
    Error_Handler();
  }

  /** Configure Regular Channel
  */
  sConfig.Channel = ADC_CHANNEL_12;
  sConfig.Rank = ADC_REGULAR_RANK_4;
  if (HAL_ADC_ConfigChannel(&hadc2, &sConfig) != HAL_OK)
  {
    Error_Handler();
  }

  /** Configure Regular Channel
  */
  sConfig.Channel = ADC_CHANNEL_13;
  sConfig.Rank = ADC_REGULAR_RANK_5;
  if (HAL_ADC_ConfigChannel(&hadc2, &sConfig) != HAL_OK)
  {
    Error_Handler();
  }

  /** Configure Regular Channel
  */
  sConfig.Channel = ADC_CHANNEL_17;
  sConfig.Rank = ADC_REGULAR_RANK_6;
  if (HAL_ADC_ConfigChannel(&hadc2, &sConfig) != HAL_OK)
  {
    Error_Handler();
  }

}

static void MX_I2C1_Init(void)
{

  hi2c1.Instance = I2C1;
  hi2c1.Init.Timing = 0x4052060F;
  hi2c1.Init.OwnAddress1 = 0;
  hi2c1.Init.AddressingMode = I2C_ADDRESSINGMODE_7BIT;
  hi2c1.Init.DualAddressMode = I2C_DUALADDRESS_DISABLE;
  hi2c1.Init.OwnAddress2 = 0;
  hi2c1.Init.OwnAddress2Masks = I2C_OA2_NOMASK;
  hi2c1.Init.GeneralCallMode = I2C_GENERALCALL_DISABLE;
  hi2c1.Init.NoStretchMode = I2C_NOSTRETCH_DISABLE;
  if (HAL_I2C_Init(&hi2c1) != HAL_OK)
  {
    Error_Handler();
  }

  /** Configure Analogue filter
  */
  if (HAL_I2CEx_ConfigAnalogFilter(&hi2c1, I2C_ANALOGFILTER_ENABLE) != HAL_OK)
  {
    Error_Handler();
  }

  /** Configure Digital filter
  */
  if (HAL_I2CEx_ConfigDigitalFilter(&hi2c1, 0) != HAL_OK)
  {
    Error_Handler();
  }

  /** I2C Fast mode Plus enable
  */
  HAL_I2CEx_EnableFastModePlus(I2C_FASTMODEPLUS_I2C1);

}

static void MX_I2C2_Init(void)
{

  hi2c2.Instance = I2C2;
  hi2c2.Init.Timing = 0x4052060F;
  hi2c2.Init.OwnAddress1 = 0;
  hi2c2.Init.AddressingMode = I2C_ADDRESSINGMODE_7BIT;
  hi2c2.Init.DualAddressMode = I2C_DUALADDRESS_DISABLE;
  hi2c2.Init.OwnAddress2 = 0;
  hi2c2.Init.OwnAddress2Masks = I2C_OA2_NOMASK;
  hi2c2.Init.GeneralCallMode = I2C_GENERALCALL_DISABLE;
  hi2c2.Init.NoStretchMode = I2C_NOSTRETCH_DISABLE;
  if (HAL_I2C_Init(&hi2c2) != HAL_OK)
  {
    Error_Handler();
  }

  /** Configure Analogue filter
  */
  if (HAL_I2CEx_ConfigAnalogFilter(&hi2c2, I2C_ANALOGFILTER_ENABLE) != HAL_OK)
  {
    Error_Handler();
  }

  /** Configure Digital filter
  */
  if (HAL_I2CEx_ConfigDigitalFilter(&hi2c2, 0) != HAL_OK)
  {
    Error_Handler();
  }

  /** I2C Fast mode Plus enable
  */
  HAL_I2CEx_EnableFastModePlus(I2C_FASTMODEPLUS_I2C2);

}

static void MX_LPUART1_UART_Init(void)
{

  hlpuart1.Instance = LPUART1;
  hlpuart1.Init.BaudRate = 115200;
  hlpuart1.Init.WordLength = UART_WORDLENGTH_8B;
  hlpuart1.Init.StopBits = UART_STOPBITS_1;
  hlpuart1.Init.Parity = UART_PARITY_NONE;
  hlpuart1.Init.Mode = UART_MODE_RX;
  hlpuart1.Init.HwFlowCtl = UART_HWCONTROL_NONE;
  hlpuart1.Init.OneBitSampling = UART_ONE_BIT_SAMPLE_DISABLE;
  hlpuart1.Init.ClockPrescaler = UART_PRESCALER_DIV1;
  hlpuart1.AdvancedInit.AdvFeatureInit = UART_ADVFEATURE_NO_INIT;
  if (HAL_HalfDuplex_Init(&hlpuart1) != HAL_OK)
  {
    Error_Handler();
  }
  if (HAL_UARTEx_SetTxFifoThreshold(&hlpuart1, UART_TXFIFO_THRESHOLD_1_8) != HAL_OK)
  {
    Error_Handler();
  }
  if (HAL_UARTEx_SetRxFifoThreshold(&hlpuart1, UART_RXFIFO_THRESHOLD_1_8) != HAL_OK)
  {
    Error_Handler();
  }
  if (HAL_UARTEx_DisableFifoMode(&hlpuart1) != HAL_OK)
  {
    Error_Handler();
  }

}

static void MX_UART4_Init(void)
{

  huart4.Instance = UART4;
  huart4.Init.BaudRate = 115200;
  huart4.Init.WordLength = UART_WORDLENGTH_8B;
  huart4.Init.StopBits = UART_STOPBITS_1;
  huart4.Init.Parity = UART_PARITY_NONE;
  huart4.Init.Mode = UART_MODE_RX;
  huart4.Init.HwFlowCtl = UART_HWCONTROL_NONE;
  huart4.Init.OverSampling = UART_OVERSAMPLING_16;
  huart4.Init.OneBitSampling = UART_ONE_BIT_SAMPLE_DISABLE;
  huart4.Init.ClockPrescaler = UART_PRESCALER_DIV1;
  huart4.AdvancedInit.AdvFeatureInit = UART_ADVFEATURE_NO_INIT;
  if (HAL_HalfDuplex_Init(&huart4) != HAL_OK)
  {
    Error_Handler();
  }
  if (HAL_UARTEx_SetTxFifoThreshold(&huart4, UART_TXFIFO_THRESHOLD_1_8) != HAL_OK)
  {
    Error_Handler();
  }
  if (HAL_UARTEx_SetRxFifoThreshold(&huart4, UART_RXFIFO_THRESHOLD_1_8) != HAL_OK)
  {
    Error_Handler();
  }
  if (HAL_UARTEx_DisableFifoMode(&huart4) != HAL_OK)
  {
    Error_Handler();
  }

}

static void MX_USART2_UART_Init(void)
{

  huart2.Instance = USART2;
  huart2.Init.BaudRate = 115200;
  huart2.Init.WordLength = UART_WORDLENGTH_8B;
  huart2.Init.StopBits = UART_STOPBITS_1;
  huart2.Init.Parity = UART_PARITY_NONE;
  huart2.Init.Mode = UART_MODE_TX_RX;
  huart2.Init.HwFlowCtl = UART_HWCONTROL_NONE;
  huart2.Init.OverSampling = UART_OVERSAMPLING_16;
  huart2.Init.OneBitSampling = UART_ONE_BIT_SAMPLE_DISABLE;
  huart2.Init.ClockPrescaler = UART_PRESCALER_DIV1;
  huart2.AdvancedInit.AdvFeatureInit = UART_ADVFEATURE_NO_INIT;
  if (HAL_UART_Init(&huart2) != HAL_OK)
  {
    Error_Handler();
  }
  if (HAL_UARTEx_SetTxFifoThreshold(&huart2, UART_TXFIFO_THRESHOLD_1_8) != HAL_OK)
  {
    Error_Handler();
  }
  if (HAL_UARTEx_SetRxFifoThreshold(&huart2, UART_RXFIFO_THRESHOLD_1_8) != HAL_OK)
  {
    Error_Handler();
  }
  if (HAL_UARTEx_DisableFifoMode(&huart2) != HAL_OK)
  {
    Error_Handler();
  }

}

static void MX_USART3_UART_Init(void)
{

  huart3.Instance = USART3;
  huart3.Init.BaudRate = 115200;
  huart3.Init.WordLength = UART_WORDLENGTH_8B;
  huart3.Init.StopBits = UART_STOPBITS_1;
  huart3.Init.Parity = UART_PARITY_NONE;
  huart3.Init.Mode = UART_MODE_RX;
  huart3.Init.HwFlowCtl = UART_HWCONTROL_NONE;
  huart3.Init.OverSampling = UART_OVERSAMPLING_16;
  huart3.Init.OneBitSampling = UART_ONE_BIT_SAMPLE_DISABLE;
  huart3.Init.ClockPrescaler = UART_PRESCALER_DIV1;
  huart3.AdvancedInit.AdvFeatureInit = UART_ADVFEATURE_NO_INIT;
  if (HAL_HalfDuplex_Init(&huart3) != HAL_OK)
  {
    Error_Handler();
  }
  if (HAL_UARTEx_SetTxFifoThreshold(&huart3, UART_TXFIFO_THRESHOLD_1_8) != HAL_OK)
  {
    Error_Handler();
  }
  if (HAL_UARTEx_SetRxFifoThreshold(&huart3, UART_RXFIFO_THRESHOLD_1_8) != HAL_OK)
  {
    Error_Handler();
  }
  if (HAL_UARTEx_DisableFifoMode(&huart3) != HAL_OK)
  {
    Error_Handler();
  }

}

static void MX_SPI2_Init(void)
{

  /* SPI2 parameter configuration*/
  hspi2.Instance = SPI2;
  hspi2.Init.Mode = SPI_MODE_MASTER;
  hspi2.Init.Direction = SPI_DIRECTION_2LINES;
  hspi2.Init.DataSize = SPI_DATASIZE_16BIT;
  hspi2.Init.CLKPolarity = SPI_POLARITY_LOW;
  hspi2.Init.CLKPhase = SPI_PHASE_2EDGE;
  hspi2.Init.NSS = SPI_NSS_SOFT;
  hspi2.Init.BaudRatePrescaler = SPI_BAUDRATEPRESCALER_64;
  hspi2.Init.FirstBit = SPI_FIRSTBIT_MSB;
  hspi2.Init.TIMode = SPI_TIMODE_DISABLE;
  hspi2.Init.CRCCalculation = SPI_CRCCALCULATION_DISABLE;
  hspi2.Init.CRCPolynomial = 7;
  hspi2.Init.CRCLength = SPI_CRC_LENGTH_DATASIZE;
  hspi2.Init.NSSPMode = SPI_NSS_PULSE_DISABLE;
  if (HAL_SPI_Init(&hspi2) != HAL_OK)
  {
    Error_Handler();
  }

}

static void MX_TIM1_Init(void)
{

  TIM_MasterConfigTypeDef sMasterConfig = {0};

  htim1.Instance = TIM1;
  htim1.Init.Prescaler = 17000-1;
  htim1.Init.CounterMode = TIM_COUNTERMODE_UP;
  htim1.Init.Period = 65535;
  htim1.Init.ClockDivision = TIM_CLOCKDIVISION_DIV1;
  htim1.Init.RepetitionCounter = 0;
  htim1.Init.AutoReloadPreload = TIM_AUTORELOAD_PRELOAD_DISABLE;
  if (HAL_TIM_OnePulse_Init(&htim1, TIM_OPMODE_SINGLE) != HAL_OK)
  {
    Error_Handler();
  }
  sMasterConfig.MasterOutputTrigger = TIM_TRGO_RESET;
  sMasterConfig.MasterOutputTrigger2 = TIM_TRGO2_RESET;
  sMasterConfig.MasterSlaveMode = TIM_MASTERSLAVEMODE_DISABLE;
  if (HAL_TIMEx_MasterConfigSynchronization(&htim1, &sMasterConfig) != HAL_OK)
  {
    Error_Handler();
  }

}

static void MX_TIM2_Init(void)
{

  TIM_MasterConfigTypeDef sMasterConfig = {0};

  htim2.Instance = TIM2;
  htim2.Init.Prescaler = 17000-1;
  htim2.Init.CounterMode = TIM_COUNTERMODE_UP;
  htim2.Init.Period = 65535;
  htim2.Init.ClockDivision = TIM_CLOCKDIVISION_DIV1;
  htim2.Init.AutoReloadPreload = TIM_AUTORELOAD_PRELOAD_DISABLE;
  if (HAL_TIM_OnePulse_Init(&htim2, TIM_OPMODE_SINGLE) != HAL_OK)
  {
    Error_Handler();
  }
  sMasterConfig.MasterOutputTrigger = TIM_TRGO_RESET;
  sMasterConfig.MasterSlaveMode = TIM_MASTERSLAVEMODE_DISABLE;
  if (HAL_TIMEx_MasterConfigSynchronization(&htim2, &sMasterConfig) != HAL_OK)
  {
    Error_Handler();
  }

}

static void MX_TIM4_Init(void)
{

  TIM_MasterConfigTypeDef sMasterConfig = {0};
  TIM_OC_InitTypeDef sConfigOC = {0};

  htim4.Instance = TIM4;
  htim4.Init.Prescaler = 17-1;
  htim4.Init.CounterMode = TIM_COUNTERMODE_UP;
  htim4.Init.Period = 999;
  htim4.Init.ClockDivision = TIM_CLOCKDIVISION_DIV1;
  htim4.Init.AutoReloadPreload = TIM_AUTORELOAD_PRELOAD_DISABLE;
  if (HAL_TIM_PWM_Init(&htim4) != HAL_OK)
  {
    Error_Handler();
  }
  sMasterConfig.MasterOutputTrigger = TIM_TRGO_RESET;
  sMasterConfig.MasterSlaveMode = TIM_MASTERSLAVEMODE_DISABLE;
  if (HAL_TIMEx_MasterConfigSynchronization(&htim4, &sMasterConfig) != HAL_OK)
  {
    Error_Handler();
  }
  sConfigOC.OCMode = TIM_OCMODE_PWM1;
  sConfigOC.Pulse = 0;
  sConfigOC.OCPolarity = TIM_OCPOLARITY_HIGH;
  sConfigOC.OCFastMode = TIM_OCFAST_DISABLE;
  if (HAL_TIM_PWM_ConfigChannel(&htim4, &sConfigOC, TIM_CHANNEL_1) != HAL_OK)
  {
    Error_Handler();
  }
  if (HAL_TIM_PWM_ConfigChannel(&htim4, &sConfigOC, TIM_CHANNEL_2) != HAL_OK)
  {
    Error_Handler();
  }
  HAL_TIM_MspPostInit(&htim4);

}

static void MX_TIM6_Init(void)
{

  TIM_MasterConfigTypeDef sMasterConfig = {0};

  htim6.Instance = TIM6;
  htim6.Init.Prescaler = 1700-1;
  htim6.Init.CounterMode = TIM_COUNTERMODE_UP;
  htim6.Init.Period = 4999;
  htim6.Init.AutoReloadPreload = TIM_AUTORELOAD_PRELOAD_DISABLE;
  if (HAL_TIM_Base_Init(&htim6) != HAL_OK)
  {
    Error_Handler();
  }
  sMasterConfig.MasterOutputTrigger = TIM_TRGO_RESET;
  sMasterConfig.MasterSlaveMode = TIM_MASTERSLAVEMODE_DISABLE;
  if (HAL_TIMEx_MasterConfigSynchronization(&htim6, &sMasterConfig) != HAL_OK)
  {
    Error_Handler();
  }

}

static void MX_TIM7_Init(void)
{

  TIM_MasterConfigTypeDef sMasterConfig = {0};

  htim7.Instance = TIM7;
  htim7.Init.Prescaler = 170-1;
  htim7.Init.CounterMode = TIM_COUNTERMODE_UP;
  htim7.Init.Period = 65534;
  htim7.Init.AutoReloadPreload = TIM_AUTORELOAD_PRELOAD_DISABLE;
  if (HAL_TIM_Base_Init(&htim7) != HAL_OK)
  {
    Error_Handler();
  }
  sMasterConfig.MasterOutputTrigger = TIM_TRGO_RESET;
  sMasterConfig.MasterSlaveMode = TIM_MASTERSLAVEMODE_DISABLE;
  if (HAL_TIMEx_MasterConfigSynchronization(&htim7, &sMasterConfig) != HAL_OK)
  {
    Error_Handler();
  }

}

static void MX_TIM8_Init(void)
{

  TIM_MasterConfigTypeDef sMasterConfig = {0};
  TIM_OC_InitTypeDef sConfigOC = {0};
  TIM_BreakDeadTimeConfigTypeDef sBreakDeadTimeConfig = {0};

  htim8.Instance = TIM8;
  htim8.Init.Prescaler = 17-1;
  htim8.Init.CounterMode = TIM_COUNTERMODE_UP;
  htim8.Init.Period = 999;
  htim8.Init.ClockDivision = TIM_CLOCKDIVISION_DIV1;
  htim8.Init.RepetitionCounter = 0;
  htim8.Init.AutoReloadPreload = TIM_AUTORELOAD_PRELOAD_DISABLE;
  if (HAL_TIM_PWM_Init(&htim8) != HAL_OK)
  {
    Error_Handler();
  }
  sMasterConfig.MasterOutputTrigger = TIM_TRGO_RESET;
  sMasterConfig.MasterOutputTrigger2 = TIM_TRGO2_RESET;
  sMasterConfig.MasterSlaveMode = TIM_MASTERSLAVEMODE_DISABLE;
  if (HAL_TIMEx_MasterConfigSynchronization(&htim8, &sMasterConfig) != HAL_OK)
  {
    Error_Handler();
  }
  sConfigOC.OCMode = TIM_OCMODE_PWM1;
  sConfigOC.Pulse = 0;
  sConfigOC.OCPolarity = TIM_OCPOLARITY_HIGH;
  sConfigOC.OCNPolarity = TIM_OCNPOLARITY_HIGH;
  sConfigOC.OCFastMode = TIM_OCFAST_DISABLE;
  sConfigOC.OCIdleState = TIM_OCIDLESTATE_RESET;
  sConfigOC.OCNIdleState = TIM_OCNIDLESTATE_RESET;
  if (HAL_TIM_PWM_ConfigChannel(&htim8, &sConfigOC, TIM_CHANNEL_1) != HAL_OK)
  {
    Error_Handler();
  }
  if (HAL_TIM_PWM_ConfigChannel(&htim8, &sConfigOC, TIM_CHANNEL_3) != HAL_OK)
  {
    Error_Handler();
  }
  sBreakDeadTimeConfig.OffStateRunMode = TIM_OSSR_DISABLE;
  sBreakDeadTimeConfig.OffStateIDLEMode = TIM_OSSI_DISABLE;
  sBreakDeadTimeConfig.LockLevel = TIM_LOCKLEVEL_OFF;
  sBreakDeadTimeConfig.DeadTime = 0;
  sBreakDeadTimeConfig.BreakState = TIM_BREAK_DISABLE;
  sBreakDeadTimeConfig.BreakPolarity = TIM_BREAKPOLARITY_HIGH;
  sBreakDeadTimeConfig.BreakFilter = 0;
  sBreakDeadTimeConfig.BreakAFMode = TIM_BREAK_AFMODE_INPUT;
  sBreakDeadTimeConfig.Break2State = TIM_BREAK2_DISABLE;
  sBreakDeadTimeConfig.Break2Polarity = TIM_BREAK2POLARITY_HIGH;
  sBreakDeadTimeConfig.Break2Filter = 0;
  sBreakDeadTimeConfig.Break2AFMode = TIM_BREAK_AFMODE_INPUT;
  sBreakDeadTimeConfig.AutomaticOutput = TIM_AUTOMATICOUTPUT_DISABLE;
  if (HAL_TIMEx_ConfigBreakDeadTime(&htim8, &sBreakDeadTimeConfig) != HAL_OK)
  {
    Error_Handler();
  }
  HAL_TIM_MspPostInit(&htim8);

}

static void MX_TIM15_Init(void)
{

  TIM_ClockConfigTypeDef sClockSourceConfig = {0};
  TIM_MasterConfigTypeDef sMasterConfig = {0};

  htim15.Instance = TIM15;
  htim15.Init.Prescaler = 170-1;
  htim15.Init.CounterMode = TIM_COUNTERMODE_UP;
  htim15.Init.Period = 999;
  htim15.Init.ClockDivision = TIM_CLOCKDIVISION_DIV1;
  htim15.Init.RepetitionCounter = 0;
  htim15.Init.AutoReloadPreload = TIM_AUTORELOAD_PRELOAD_DISABLE;
  if (HAL_TIM_Base_Init(&htim15) != HAL_OK)
  {
    Error_Handler();
  }
  sClockSourceConfig.ClockSource = TIM_CLOCKSOURCE_INTERNAL;
  if (HAL_TIM_ConfigClockSource(&htim15, &sClockSourceConfig) != HAL_OK)
  {
    Error_Handler();
  }
  sMasterConfig.MasterOutputTrigger = TIM_TRGO_RESET;
  sMasterConfig.MasterSlaveMode = TIM_MASTERSLAVEMODE_DISABLE;
  if (HAL_TIMEx_MasterConfigSynchronization(&htim15, &sMasterConfig) != HAL_OK)
  {
    Error_Handler();
  }

}

static void MX_TIM16_Init(void)
{

  htim16.Instance = TIM16;
  htim16.Init.Prescaler = 1700-1;
  htim16.Init.CounterMode = TIM_COUNTERMODE_UP;
  htim16.Init.Period = 999;
  htim16.Init.ClockDivision = TIM_CLOCKDIVISION_DIV1;
  htim16.Init.RepetitionCounter = 0;
  htim16.Init.AutoReloadPreload = TIM_AUTORELOAD_PRELOAD_DISABLE;
  if (HAL_TIM_Base_Init(&htim16) != HAL_OK)
  {
    Error_Handler();
  }

}

static void MX_TIM17_Init(void)
{

  htim17.Instance = TIM17;
  htim17.Init.Prescaler = 1700-1;
  htim17.Init.CounterMode = TIM_COUNTERMODE_UP;
  htim17.Init.Period = 3999;
  htim17.Init.ClockDivision = TIM_CLOCKDIVISION_DIV1;
  htim17.Init.RepetitionCounter = 0;
  htim17.Init.AutoReloadPreload = TIM_AUTORELOAD_PRELOAD_DISABLE;
  if (HAL_TIM_Base_Init(&htim17) != HAL_OK)
  {
    Error_Handler();
  }

}

static void MX_DMA_Init(void)
{

  /* DMA controller clock enable */
  __HAL_RCC_DMAMUX1_CLK_ENABLE();
  __HAL_RCC_DMA1_CLK_ENABLE();
  __HAL_RCC_DMA2_CLK_ENABLE();

  /* DMA interrupt init */
  /* DMA1_Channel1_IRQn interrupt configuration */
  HAL_NVIC_SetPriority(DMA1_Channel1_IRQn, 0, 0);
  HAL_NVIC_EnableIRQ(DMA1_Channel1_IRQn);
  /* DMA1_Channel2_IRQn interrupt configuration */
  HAL_NVIC_SetPriority(DMA1_Channel2_IRQn, 0, 0);
  HAL_NVIC_EnableIRQ(DMA1_Channel2_IRQn);
  /* DMA1_Channel3_IRQn interrupt configuration */
  HAL_NVIC_SetPriority(DMA1_Channel3_IRQn, 0, 0);
  HAL_NVIC_EnableIRQ(DMA1_Channel3_IRQn);
  /* DMA1_Channel4_IRQn interrupt configuration */
  HAL_NVIC_SetPriority(DMA1_Channel4_IRQn, 0, 0);
  HAL_NVIC_EnableIRQ(DMA1_Channel4_IRQn);
  /* DMA1_Channel5_IRQn interrupt configuration */
  HAL_NVIC_SetPriority(DMA1_Channel5_IRQn, 0, 0);
  HAL_NVIC_EnableIRQ(DMA1_Channel5_IRQn);
  /* DMA1_Channel6_IRQn interrupt configuration */
  HAL_NVIC_SetPriority(DMA1_Channel6_IRQn, 0, 0);
  HAL_NVIC_EnableIRQ(DMA1_Channel6_IRQn);
  /* DMA2_Channel1_IRQn interrupt configuration */
  HAL_NVIC_SetPriority(DMA2_Channel1_IRQn, 1, 0);
  HAL_NVIC_EnableIRQ(DMA2_Channel1_IRQn);
  /* DMA2_Channel2_IRQn interrupt configuration */
  HAL_NVIC_SetPriority(DMA2_Channel2_IRQn, 1, 0);
  HAL_NVIC_EnableIRQ(DMA2_Channel2_IRQn);

}

static void MX_GPIO_Init(void)
{
  GPIO_InitTypeDef GPIO_InitStruct = {0};

  /* GPIO Ports Clock Enable */
  __HAL_RCC_GPIOC_CLK_ENABLE();
  __HAL_RCC_GPIOF_CLK_ENABLE();
  __HAL_RCC_GPIOG_CLK_ENABLE();
  __HAL_RCC_GPIOA_CLK_ENABLE();
  __HAL_RCC_GPIOB_CLK_ENABLE();

  /*Configure GPIO pin Output Level */
  HAL_GPIO_WritePin(GPIOA, DRV_CS_2_Pin|DRV_CS_1_Pin, GPIO_PIN_SET);

  /*Configure GPIO pin Output Level */
  HAL_GPIO_WritePin(LED_BLUE_GPIO_Port, LED_BLUE_Pin, GPIO_PIN_RESET);

  /*Configure GPIO pin Output Level */
  HAL_GPIO_WritePin(LED_RED_GPIO_Port, LED_RED_Pin, GPIO_PIN_RESET);

  /*Configure GPIO pin Output Level */
  HAL_GPIO_WritePin(LED_GREEN_GPIO_Port, LED_GREEN_Pin, GPIO_PIN_RESET);

  /*Configure GPIO pins : JOY3_Pin JOY2_Pin JOY1_Pin JOY4_Pin */
  GPIO_InitStruct.Pin = JOY3_Pin|JOY2_Pin|JOY1_Pin|JOY4_Pin;
  GPIO_InitStruct.Mode = GPIO_MODE_INPUT;
  GPIO_InitStruct.Pull = GPIO_PULLUP;
  HAL_GPIO_Init(GPIOC, &GPIO_InitStruct);

  /*Configure GPIO pin : JOY5_Pin */
  GPIO_InitStruct.Pin = JOY5_Pin;
  GPIO_InitStruct.Mode = GPIO_MODE_INPUT;
  GPIO_InitStruct.Pull = GPIO_PULLUP;
  HAL_GPIO_Init(JOY5_GPIO_Port, &GPIO_InitStruct);

  /*Configure GPIO pins : DRV_CS_2_Pin DRV_CS_1_Pin LED_BLUE_Pin */
  GPIO_InitStruct.Pin = DRV_CS_2_Pin|DRV_CS_1_Pin|LED_BLUE_Pin;
  GPIO_InitStruct.Mode = GPIO_MODE_OUTPUT_PP;
  GPIO_InitStruct.Pull = GPIO_NOPULL;
  GPIO_InitStruct.Speed = GPIO_SPEED_FREQ_LOW;
  HAL_GPIO_Init(GPIOA, &GPIO_InitStruct);

  /*Configure GPIO pin : START_MOD_IR_Pin */
  GPIO_InitStruct.Pin = START_MOD_IR_Pin;
  GPIO_InitStruct.Mode = GPIO_MODE_IT_RISING_FALLING;
  GPIO_InitStruct.Pull = GPIO_NOPULL;
  HAL_GPIO_Init(START_MOD_IR_GPIO_Port, &GPIO_InitStruct);

  /*Configure GPIO pin : LED_RED_Pin */
  GPIO_InitStruct.Pin = LED_RED_Pin;
  GPIO_InitStruct.Mode = GPIO_MODE_OUTPUT_PP;
  GPIO_InitStruct.Pull = GPIO_NOPULL;
  GPIO_InitStruct.Speed = GPIO_SPEED_FREQ_LOW;
  HAL_GPIO_Init(LED_RED_GPIO_Port, &GPIO_InitStruct);

  /*Configure GPIO pin : LED_GREEN_Pin */
  GPIO_InitStruct.Pin = LED_GREEN_Pin;
  GPIO_InitStruct.Mode = GPIO_MODE_OUTPUT_PP;
  GPIO_InitStruct.Pull = GPIO_NOPULL;
  GPIO_InitStruct.Speed = GPIO_SPEED_FREQ_LOW;
  HAL_GPIO_Init(LED_GREEN_GPIO_Port, &GPIO_InitStruct);

  /* EXTI interrupt init*/
  HAL_NVIC_SetPriority(EXTI15_10_IRQn, 0, 0);
  HAL_NVIC_EnableIRQ(EXTI15_10_IRQn);

}

/* USER CODE BEGIN 4 */
void HAL_TIM_PeriodElapsedCallback(TIM_HandleTypeDef *htim)
{
	if (htim->Instance == TIM6) //bout 20Hz, start mod leds
	{
		InterruptStartModLeds();
	}
	if (htim->Instance == TIM7) //65.5ms, 1Mhz clock, start mod
	{
		InterruptStartMod(TIMEOUT);
	}
	if (htim->Instance == TIM15) //1kHz
	{
		ADC_REDOUT_INFO_GETTHEMALL(&Eva, &Motors, &Lines, ADC1_BUFFER, ADC2_BUFFER);
		static uint8_t changedRotationDirection=false;
		Eva.InBattle = StartModule_Started();
		if(Eva.InBattle && changedRotationDirection == false)
		{
			changedRotationDirection = true;
			before_attack_rotation_direction = lastSeen;
		}
		if(Eva.InBattle == false && changedRotationDirection)
		{
			SET_MOTORS(0,0);
	    	TIM4->CCR1 = 0;
	    	TIM4->CCR2 = 0;
			TIM8->CCR1 = 0;
			TIM8->CCR3 = 0;
			changedRotationDirection = false;
		}

		if(Eva.InBattle)
		{
			if(Eva.AttackMode == STRAIGHT)
				STRAIGHT_ATTACK();
			else if(Eva.AttackMode == CURVE)
				CURVE_ATTACK(lastSeen);
			else if(Eva.AttackMode == FOLLOW_LINER)
				FOLLOWLINER_ATTACK(lastSeen);
			else if(Eva.AttackMode == FOLLOW_ATTACKER)
				FOLLOW_ATTACKER_ATTACK(lastSeen);
			else if(Eva.AttackMode == STRAIGHT_FLAGS)
				STRAIGHT_ATTACK_FLAGS();
			else if(Eva.AttackMode == CURVE_FLAGS)
				CURVE_ATTACK_FLAGS();
			else
				STRAIGHT_ATTACK();
		}
	}
	if (htim->Instance == TIM16) //100Hz
	{
		WATCHDOG();
		LOAD_PERFORMANCE_CALCULATION();
	}
	if (htim->Instance == TIM17) //25Hz
	{
		OLED_INFO();
	}
}

void HAL_GPIO_EXTI_Callback(uint16_t GPIO_Pin)
{
    if (GPIO_Pin == START_MOD_IR_Pin)
    {
        if (HAL_GPIO_ReadPin(START_MOD_IR_GPIO_Port, START_MOD_IR_Pin) == GPIO_PIN_SET)
            StartMod_OnRisingExti();
        else
            StartMod_OnFallingExti();
    }
}

void LOAD_PERFORMANCE_CALCULATION()
{
   //LOAD
	uint32_t total = DWT->CYCCNT;
	uint32_t total_diff = total - last_total;
	uint32_t idle_diff  = cpu_idle_cycles - last_idle;

	last_total = total;
	last_idle = cpu_idle_cycles;

	if (total_diff > 0)
		cpu_load_permille = (1000U * (total_diff - idle_diff)) / total_diff;
	else
		cpu_load_permille = 0;

	MCU_LOAD = cpu_load_permille / 10;

	//================================ MEDIAN FILTERING, MCU temp
	static uint16_t FILTER_ARRAY[MCU_USAGE_FILTRATION_ARRAY_SIZE];
	static uint16_t FILTER_INDX=0;
	static uint16_t CURRENT=0;

	CURRENT = MCU_LOAD;
	FILTER_ARRAY[FILTER_INDX] = CURRENT;
	FILTER_INDX = (FILTER_INDX + 1) % MCU_USAGE_FILTRATION_ARRAY_SIZE;

	Eva.MCU_USAGE = GET_MEDIAN(FILTER_ARRAY, MCU_USAGE_FILTRATION_ARRAY_SIZE);
}

void HAL_UARTEx_RxEventCallback(UART_HandleTypeDef *huart, uint16_t size)
{
	TFLUNAs_DMA_CALLBACK(&Lunas, huart);
}

static inline void DWT_Init(void)
{
    CoreDebug->DEMCR |= CoreDebug_DEMCR_TRCENA_Msk;
    DWT->CYCCNT = 0;
    DWT->CTRL |= DWT_CTRL_CYCCNTENA_Msk;
}

/* USER CODE END 4 */

void Error_Handler(void)
{
  /* USER CODE BEGIN Error_Handler_Debug */
	HAL_GPIO_WritePin(LED_RED_GPIO_Port, LED_RED_Pin, 1);
	HAL_GPIO_WritePin(LED_GREEN_GPIO_Port, LED_GREEN_Pin, 0);
	HAL_GPIO_WritePin(LED_BLUE_GPIO_Port, LED_BLUE_Pin, 0);
	dupa=67;
  /* User can add his own implementation to report the HAL error return state */
  __disable_irq();
  while (1)
  {
  }
  /* USER CODE END Error_Handler_Debug */
}
